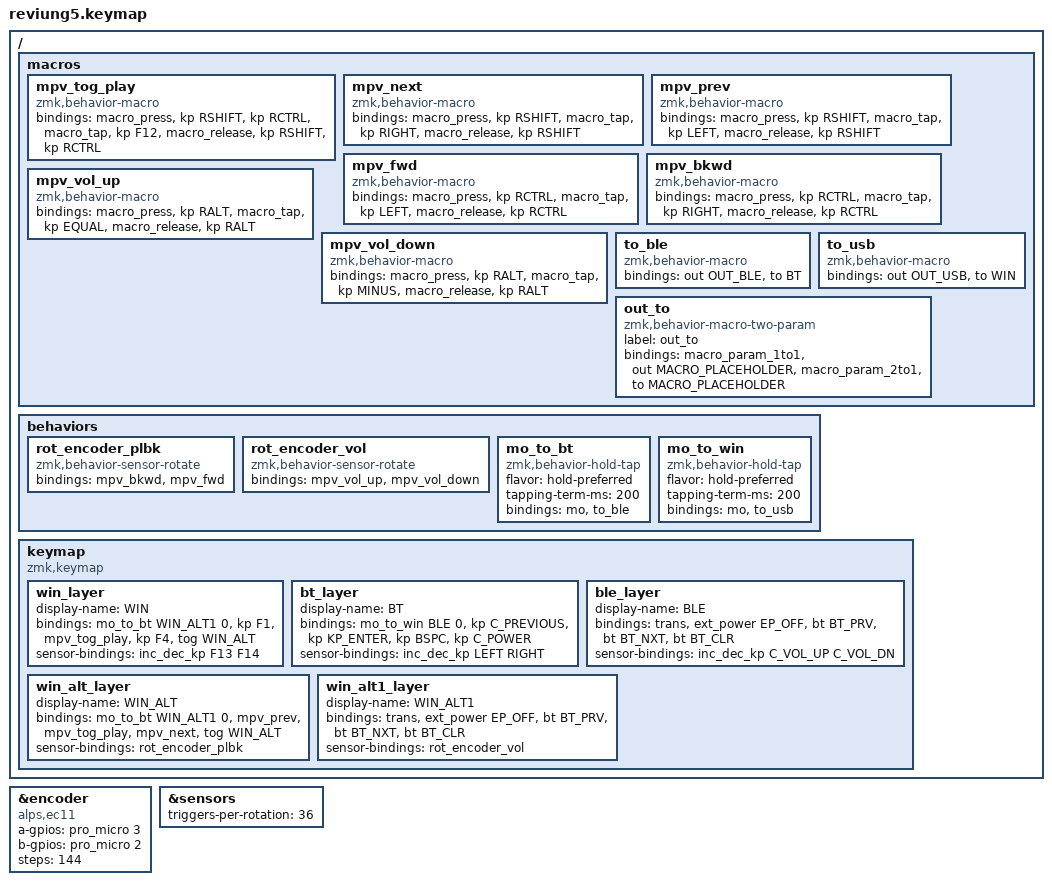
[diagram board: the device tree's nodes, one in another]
/*
 * Copyright (c) 2022 The ZMK Contributors
 *
 * SPDX-License-Identifier: MIT
 */

#include <behaviors.dtsi>
#include <dt-bindings/zmk/keys.h>
#include <dt-bindings/zmk/bt.h>
#include <dt-bindings/zmk/outputs.h>
#include <dt-bindings/zmk/ext_power.h>

#define WIN 0
#define BT 1
#define BLE 2
#define WIN_ALT 3
#define WIN_ALT1 4

&encoder {
  compatible = "alps,ec11";
  a-gpios = <&pro_micro 3 (GPIO_PULL_UP)>;
  b-gpios = <&pro_micro 2 (GPIO_PULL_UP)>;
  steps = <144>;
  status = "okay";
};

&sensors {
  triggers-per-rotation = <36>;
};

/ {
    macros {
        mpv_tog_play: mpv_tog_play {
            compatible = "zmk,behavior-macro";
            #binding-cells = <0>;
            bindings
                = <&macro_press &kp RSHIFT &kp RCTRL>
                , <&macro_tap &kp F12>
                , <&macro_release &kp RSHIFT &kp RCTRL>
                ;
        };
        mpv_next: mpv_next {
            compatible = "zmk,behavior-macro";
            #binding-cells = <0>;
            bindings
                = <&macro_press &kp RSHIFT>
                , <&macro_tap &kp RIGHT>
                , <&macro_release &kp RSHIFT>
                ;
        };
        mpv_prev: mpv_prev {
            compatible = "zmk,behavior-macro";
            #binding-cells = <0>;
            bindings
                = <&macro_press &kp RSHIFT>
                , <&macro_tap &kp LEFT>
                , <&macro_release &kp RSHIFT>
                ;
        };
        mpv_fwd: mpv_fwd {
            compatible = "zmk,behavior-macro";
            #binding-cells = <0>;
            bindings
                = <&macro_press &kp RCTRL>
                , <&macro_tap &kp LEFT>
                , <&macro_release &kp RCTRL>
                ;
        };
        mpv_bkwd: mpv_bkwd {
            compatible = "zmk,behavior-macro";
            #binding-cells = <0>;
            bindings
                = <&macro_press &kp RCTRL>
                , <&macro_tap &kp RIGHT>
                , <&macro_release &kp RCTRL>
                ;
        };
	mpv_vol_up: mpv_vol_up {
            compatible = "zmk,behavior-macro";
            #binding-cells = <0>;
            bindings
                = <&macro_press &kp RALT>
                , <&macro_tap &kp EQUAL>
                , <&macro_release &kp RALT>
                ;
        };
        mpv_vol_down: mpv_vol_down {
            compatible = "zmk,behavior-macro";
            #binding-cells = <0>;
            bindings
                = <&macro_press &kp RALT>
                , <&macro_tap &kp MINUS>
                , <&macro_release &kp RALT>
                ;
        };
        to_ble: to_ble {
            compatible = "zmk,behavior-macro";
            #binding-cells = <0>;
            bindings
                = <&out OUT_BLE>
                , <&to BT>
                ;
        };
        to_usb: to_usb {
            compatible = "zmk,behavior-macro";
            #binding-cells = <0>;
            bindings
                = <&out OUT_USB>
                , <&to WIN>
                ;
        };
        out_to: out_to {
            label = "out_to";
            compatible = "zmk,behavior-macro-two-param";
            #binding-cells = <2>;
            bindings
                = <&macro_param_1to1>
                , <&out MACRO_PLACEHOLDER>
                , <&macro_param_2to1>
                , <&to MACRO_PLACEHOLDER>;
        };
    };
};
/ {
        behaviors {
            rot_encoder_plbk: rot_encoder_plbk {
              compatible = "zmk,behavior-sensor-rotate";
              #sensor-binding-cells = <0>;
              bindings = <&mpv_bkwd>, <&mpv_fwd>;
            };
	    rot_encoder_vol: rot_encoder_vol {
              compatible = "zmk,behavior-sensor-rotate";
              #sensor-binding-cells = <0>;
              bindings = <&mpv_vol_up>, <&mpv_vol_down>;
            };
            mo_to_bt: mo_to_bt {
              compatible = "zmk,behavior-hold-tap";
              #binding-cells = <2>;
              flavor = "hold-preferred";
              tapping-term-ms = <200>;
              bindings = <&mo>, <&to_ble>;
            };
            mo_to_win: mo_to_win {
              compatible = "zmk,behavior-hold-tap";
              #binding-cells = <2>;
              flavor = "hold-preferred";
              tapping-term-ms = <200>;
              bindings = <&mo>, <&to_usb>;
            };
        };
        keymap {
            compatible = "zmk,keymap";

            win_layer {
              display-name = "WIN";
              bindings = <
                // ╭─────────────────────────┬──────────────┬──────────────────┬─────────────┬─────────────╮
                     &mo_to_bt WIN_ALT1 0        &kp F1        &mpv_tog_play      &kp F4       &tog WIN_ALT
                // ╰─────────────────────────┴──────────────┴──────────────────┴─────────────┴─────────────╯
              >;
              sensor-bindings = <&inc_dec_kp F13 F14>;
            };

            bt_layer {
              display-name = "BT";
              bindings = <
                // ╭─────────────────────────┬────────────────────┬──────────────────┬─────────────┬─────────────╮
                     &mo_to_win BLE 0   &kp C_PREVIOUS        &kp KP_ENTER      &kp BSPC      &kp C_POWER
                // ╰─────────────────────────┴────────────────────┴──────────────────┴─────────────┴─────────────╯
              >;
              sensor-bindings = <&inc_dec_kp LEFT RIGHT>;
            };

            ble_layer {
              display-name = "BLE";
              bindings = <
                // ╭─────────────┬─────────────┬─────────────┬─────────────┬─────────────╮
                     &trans     &ext_power EP_OFF   &bt BT_PRV    &bt BT_NXT    &bt BT_CLR
                // ╰─────────────┴─────────────┴─────────────┴─────────────┴─────────────╯
              >;
              sensor-bindings = <&inc_dec_kp C_VOL_UP C_VOL_DN>;
            };

            win_alt_layer {
              display-name = "WIN_ALT";
              bindings = <
                // ╭───────────────────────┬─────────────┬───────────────────┬─────────────┬─────────────╮
                     &mo_to_bt WIN_ALT1 0     &mpv_prev      &mpv_tog_play      &mpv_next    &tog WIN_ALT 
                // ╰───────────────────────┴─────────────┴───────────────────┴─────────────┴─────────────╯
              >;
              sensor-bindings = <&rot_encoder_plbk>;
            };


            win_alt1_layer {
              display-name = "WIN_ALT1";
              bindings = <
                // ╭─────────────┬─────────────┬─────────────┬─────────────┬─────────────╮
                     &trans     &ext_power EP_OFF   &bt BT_PRV    &bt BT_NXT    &bt BT_CLR
                // ╰─────────────┴─────────────┴─────────────┴─────────────┴─────────────╯
              >;
              sensor-bindings = <&rot_encoder_vol>;
            };



        };
};
